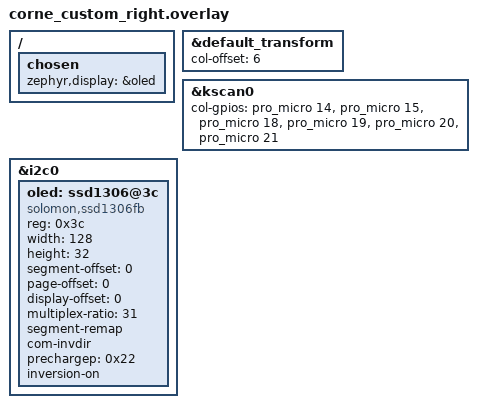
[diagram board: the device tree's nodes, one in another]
/*
 * Copyright (c) 2024
 * SPDX-License-Identifier: MIT
 */

#include "corne_custom.dtsi"

&default_transform {
    col-offset = <6>;
};

&kscan0 {
    col-gpios = <&pro_micro 14 GPIO_ACTIVE_HIGH>,
                <&pro_micro 15 GPIO_ACTIVE_HIGH>,
                <&pro_micro 18 GPIO_ACTIVE_HIGH>,
                <&pro_micro 19 GPIO_ACTIVE_HIGH>,
                <&pro_micro 20 GPIO_ACTIVE_HIGH>,
                <&pro_micro 21 GPIO_ACTIVE_HIGH>;
};

&i2c0 {
    status = "okay";

    oled: ssd1306@3c {
        compatible = "solomon,ssd1306fb";
        reg = <0x3c>;
        width = <128>;
        height = <32>;
        segment-offset = <0>;
        page-offset = <0>;
        display-offset = <0>;
        multiplex-ratio = <31>;
        segment-remap;
        com-invdir;
        prechargep = <0x22>;
        inversion-on;
    };
};

/ {
    chosen {
        zephyr,display = &oled;
    };
};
